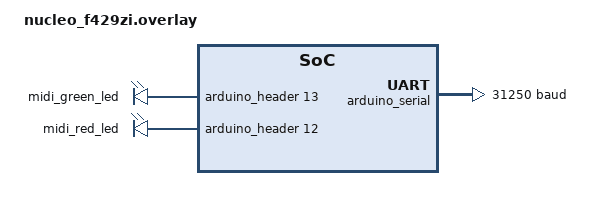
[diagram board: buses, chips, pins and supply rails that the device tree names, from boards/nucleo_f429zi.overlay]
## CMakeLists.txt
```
# Copyright (c) 2025 Titouan Christophe
# SPDX-License-Identifier: Apache-2.0

cmake_minimum_required(VERSION 3.20.0)

find_package(Zephyr REQUIRED HINTS $ENV{ZEPHYR_BASE})
project(netmidi2)

target_sources(app PRIVATE src/main.c)

include(${ZEPHYR_BASE}/samples/net/common/common.cmake)
```

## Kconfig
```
# Copyright (c) 2025 Titouan Christophe
# SPDX-License-Identifier: Apache-2.0

menu "Networking MIDI2 sample application"

config NET_SAMPLE_MIDI2_ACTIVITY_LED
	bool "Light up an LED while sending on the serial MIDI1 port"
	depends on $(dt_nodelabel_enabled,midi_green_led)
	select GPIO
	default y

config NET_SAMPLE_MIDI_HOST_PORT
	int "Host MIDI2 endpoint on this port"
	default 45486

choice NET_SAMPLE_MIDI2_AUTH_TYPE
	prompt "UMP Endpoint authentication method"
	default NET_SAMPLE_MIDI2_AUTH_NONE

config NET_SAMPLE_MIDI2_AUTH_NONE
	bool "No authentication"

config NET_SAMPLE_MIDI2_AUTH_SHARED_SECRET
	bool "Authentication with shared secret"
	select NETMIDI2_HOST_AUTH

config NET_SAMPLE_MIDI2_AUTH_USER_PASSWORD
	bool "Authentication with username+password"
	select NETMIDI2_HOST_AUTH

endchoice

config NET_SAMPLE_MIDI2_SHARED_SECRET
	string "Shared secret"
	depends on NET_SAMPLE_MIDI2_AUTH_SHARED_SECRET

config NET_SAMPLE_MIDI2_USERNAME
	string "Username"
	depends on NET_SAMPLE_MIDI2_AUTH_USER_PASSWORD

config NET_SAMPLE_MIDI2_PASSWORD
	string "Password"
	depends on NET_SAMPLE_MIDI2_AUTH_USER_PASSWORD

endmenu

source "Kconfig.zephyr"
```

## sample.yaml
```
common:
  harness: net
  tags:
    - net
sample:
  description: Test UDP transport for Universal MIDI Packets
  name: Network MIDI2
```

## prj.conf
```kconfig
CONFIG_LOG=y
CONFIG_LOG_MODE_IMMEDIATE=y
CONFIG_SYSTEM_WORKQUEUE_STACK_SIZE=8192

CONFIG_ZVFS_POLL_MAX=4

CONFIG_NETWORKING=y
CONFIG_NET_LOG=y
CONFIG_NET_IPV4=y
CONFIG_NET_UDP=y
CONFIG_NET_SOCKETS=y
CONFIG_NET_STATISTICS=y
CONFIG_NET_SOCKETS_SERVICE_STACK_SIZE=2048

CONFIG_NET_CONFIG_MY_IPV4_ADDR="192.0.2.1"
CONFIG_NET_CONFIG_NEED_IPV4=y
CONFIG_NET_CONFIG_SETTINGS=y

CONFIG_NET_HOSTNAME_ENABLE=y
CONFIG_MDNS_RESPONDER=y
CONFIG_DNS_SD=y

CONFIG_MBEDTLS=y
CONFIG_MBEDTLS_CIPHER_CCM_ENABLED=y

CONFIG_CRYPTO=y
CONFIG_CRYPTO_MBEDTLS_SHIM=y
```

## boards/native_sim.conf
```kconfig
CONFIG_NET_CONFIG_MY_IPV4_ADDR="192.0.2.1"
```

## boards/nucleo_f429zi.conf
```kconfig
CONFIG_NET_CONFIG_MY_IPV4_ADDR=""
CONFIG_NET_DHCPV4=y
```

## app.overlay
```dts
/*
 * Copyright (c) 2025 Titouan Christophe
 *
 * SPDX-License-Identifier: Apache-2.0
 */

/ {
	midi2: zephyr-midi2 {
		compatible = "zephyr,midi2-device";
		status = "okay";
		#address-cells = <1>;
		#size-cells = <1>;
		label = "Zephyr-UDP-MIDI2";

		midi2@0 {
			reg = <0 4>;
			label = "Synthesizer";
			protocol = "midi2";
		};

		midi1@8 {
			reg = <8 1>;
			protocol = "midi1-up-to-64b";
			terminal-type = "input-only";
			label = "Keyboard";
		};

		ext_midi_out: midi1@9 {
			reg = <9 1>;
			protocol = "midi1-up-to-64b";
			terminal-type = "output-only";
			label = "External output (MIDI DIN-5)";
			serial-31250bps;
		};
	};
};
```

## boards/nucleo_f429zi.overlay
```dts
#include "../app.overlay"

/ {
	aliases {
		midi-tx-uart = &arduino_serial;
		midi-tx-led = &midi_green_led;
	};

	leds {
		midi_green_led: midi-green-led {
			gpios = <&arduino_header 13 GPIO_ACTIVE_HIGH>;
		};

		midi_red_led: midi-red-led {
			gpios = <&arduino_header 12 GPIO_ACTIVE_HIGH>;
		};
	};
};

&arduino_serial {
	current-speed = <31250>;
};
```

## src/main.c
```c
/*
 * Copyright (c) 2025 Titouan Christophe
 * SPDX-License-Identifier: Apache-2.0
 */

#include <zephyr/kernel.h>
#include <errno.h>
#include <stdio.h>

#include <zephyr/audio/midi.h>
#include <zephyr/net/dns_sd.h>
#include <zephyr/net/midi2.h>

#include <ump_stream_responder.h>

#include <zephyr/logging/log.h>
LOG_MODULE_REGISTER(net_midi2_sample, LOG_LEVEL_DBG);

#define ACT_LED_NODE DT_NODELABEL(midi_green_led)
#define SERIAL_NODE  DT_NODELABEL(midi_serial)

#if !defined(CONFIG_NET_SAMPLE_MIDI2_ACTIVITY_LED)
#define CONFIGURE_LED()
#define SET_LED(_state)
#else /* CONFIG_NET_SAMPLE_MIDI2_ACTIVITY_LED */
#include <zephyr/drivers/gpio.h>

static const struct gpio_dt_spec act_led = GPIO_DT_SPEC_GET(ACT_LED_NODE, gpios);

#define CONFIGURE_LED() gpio_pin_configure_dt(&act_led, GPIO_OUTPUT_INACTIVE)
#define SET_LED(_state) gpio_pin_set_dt(&act_led, (_state))
#endif  /* CONFIG_NET_SAMPLE_MIDI2_ACTIVITY_LED */


#if !DT_NODE_EXISTS(SERIAL_NODE)
#define send_external_midi1(...)
#else /* DT_NODE_EXISTS(SERIAL_NODE) */
#include <zephyr/drivers/uart.h>

static const struct device *const uart_dev = DEVICE_DT_GET(SERIAL_NODE);

static inline void send_external_midi1(const struct midi_ump ump)
{
	/* Only send MIDI events aimed at the external output */
	if (UMP_GROUP(ump) != DT_REG_ADDR(DT_NODELABEL(ext_midi_out))) {
		return;
	}

	switch (UMP_MIDI_COMMAND(ump)) {
	case UMP_MIDI_PROGRAM_CHANGE:
		SET_LED(1);
		uart_poll_out(uart_dev, UMP_MIDI_STATUS(ump));
		uart_poll_out(uart_dev, UMP_MIDI1_P1(ump));
		SET_LED(0);
		break;

	case UMP_MIDI_NOTE_OFF:
	case UMP_MIDI_NOTE_ON:
	case UMP_MIDI_AFTERTOUCH:
	case UMP_MIDI_CONTROL_CHANGE:
	case UMP_MIDI_PITCH_BEND:
		SET_LED(1);
		uart_poll_out(uart_dev, UMP_MIDI_STATUS(ump));
		uart_poll_out(uart_dev, UMP_MIDI1_P1(ump));
		uart_poll_out(uart_dev, UMP_MIDI1_P2(ump));
		SET_LED(0);
		break;
	}
}
#endif /* DT_NODE_EXISTS(SERIAL_NODE) */

#define MIDI2_NODE DT_NODELABEL(midi2)

static const struct ump_endpoint_dt_spec ump_ep_dt =
	UMP_ENDPOINT_DT_SPEC_GET(MIDI2_NODE);

static inline void handle_ump_stream(struct netmidi2_session *session,
				     const struct midi_ump ump)
{
	const struct ump_stream_responder_cfg responder_cfg =
		UMP_STREAM_RESPONDER(session, netmidi2_send, &ump_ep_dt);
	ump_stream_respond(&responder_cfg, ump);
}

#if defined(CONFIG_NET_SAMPLE_MIDI2_AUTH_NONE)
/* Simple Network MIDI 2.0 endpoint without authentication */
NETMIDI2_EP_DEFINE(midi_server, DT_PROP_OR(MIDI2_NODE, label, NULL), NULL, htons(CONFIG_NET_SAMPLE_MIDI_HOST_PORT));

#elif defined(CONFIG_NET_SAMPLE_MIDI2_AUTH_SHARED_SECRET)
/* Network MIDI 2.0 endpoint with shared secret authentication */
BUILD_ASSERT(
	sizeof(CONFIG_NET_SAMPLE_MIDI2_SHARED_SECRET) > 1,
	"CONFIG_NET_SAMPLE_MIDI2_SHARED_SECRET must be not empty"
);


NETMIDI2_EP_DEFINE_WITH_AUTH(midi_server, DT_PROP_OR(MIDI2_NODE, label, NULL), NULL, htons(CONFIG_NET_SAMPLE_MIDI_HOST_PORT),
	CONFIG_NET_SAMPLE_MIDI2_SHARED_SECRET);

#elif defined(CONFIG_NET_SAMPLE_MIDI2_AUTH_USER_PASSWORD)
/* Network MIDI 2.0 endpoint with a single user/password*/
BUILD_ASSERT(
	sizeof(CONFIG_NET_SAMPLE_MIDI2_USERNAME) > 1,
	"CONFIG_NET_SAMPLE_MIDI2_USERNAME must be not empty"
);
BUILD_ASSERT(
	sizeof(CONFIG_NET_SAMPLE_MIDI2_PASSWORD) > 1,
	"CONFIG_NET_SAMPLE_MIDI2_PASSWORD must be not empty"
);


NETMIDI2_EP_DEFINE_WITH_USERS(midi_server, DT_PROP_OR(MIDI2_NODE, label, NULL), NULL, htons(CONFIG_NET_SAMPLE_MIDI_HOST_PORT),
	{.name = CONFIG_NET_SAMPLE_MIDI2_USERNAME,
	 .password = CONFIG_NET_SAMPLE_MIDI2_PASSWORD});

#endif

DNS_SD_REGISTER_SERVICE(midi_dns, CONFIG_NET_HOSTNAME "-" CONFIG_BOARD,
			"_midi2", "_udp", "local", DNS_SD_EMPTY_TXT,
			&midi_server.addr4.sin_port);

static void rx_ump(struct netmidi2_session *session, const struct midi_ump ump)
{
	switch (UMP_MT(ump)) {
	case UMP_MT_MIDI1_CHANNEL_VOICE:
		send_external_midi1(ump);
	case UMP_MT_UMP_STREAM:
		handle_ump_stream(session, ump);
		break;
	}
}

static void session_established(struct netmidi2_session *session)
{
	LOG_INF("New client session established %p", session);
}

static void session_closed(struct netmidi2_session *session)
{
	LOG_INF("Client session closing %p", session);
}

int main(void)
{
	CONFIGURE_LED();

	netmidi2_set_ops(&midi_server, &((const struct netmidi2_ops) {
		.rx_packet_cb = rx_ump,
		.session_established_cb = session_established,
		.session_closed_cb = session_closed,
	}));
	netmidi2_host_ep_start(&midi_server);

	return 0;
}
```

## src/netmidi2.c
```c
#include "netmidi2.h"

#include <stdio.h>
#include <zephyr/crypto/crypto.h>

#include <zephyr/logging/log.h>
LOG_MODULE_REGISTER(udp_midi, LOG_LEVEL_INF);

#define BUFSIZE 256

NET_BUF_POOL_DEFINE(udp_midi_pool, 10, BUFSIZE, 0, NULL);

#define SESS_LOG_DBG(_s, _fmt, ...) SESS_LOG(DBG, _s, _fmt, ##__VA_ARGS__)
#define SESS_LOG_INF(_s, _fmt, ...) SESS_LOG(INF, _s, _fmt, ##__VA_ARGS__)
#define SESS_LOG_WRN(_s, _fmt, ...) SESS_LOG(WRN, _s, _fmt, ##__VA_ARGS__)
#define SESS_LOG_ERR(_s, _fmt, ...) SESS_LOG(ERR, _s, _fmt, ##__VA_ARGS__)

#define SESS_LOG(_lvl, _s, _fmt, ...) \
	{ \
		const struct sockaddr_in *__pa = (const struct sockaddr_in *) &(_s)->addr; \
		char __pn[INET_ADDRSTRLEN]; \
		net_addr_ntop(AF_INET, &__pa->sin_addr, __pn, INET_ADDRSTRLEN); \
		LOG_##_lvl("%s:%d " _fmt, __pn, __pa->sin_port, ##__VA_ARGS__); \
	}

static inline bool udp_midi_session_has_state(struct udp_midi_session *session,
					      enum udp_midi_session_state state)
{
	if (! session) {
		return false;
	}
	return session->state == state;
}

static inline void udp_midi_free_session(struct udp_midi_session *session)
{
	SESS_LOG_INF(session, "Free client session");

	k_work_cancel(&session->tx_work);
	if (session->tx_buf) {
		net_buf_unref(session->tx_buf);
	}
	memset(session, 0, sizeof(*session) - sizeof(struct k_work));
}

static inline struct udp_midi_session *udp_midi_match_session(
	struct udp_midi_ep *ep,
	struct sockaddr *peer_addr,
	socklen_t peer_addr_len
)
{
	for (size_t i=0; i<ep->n_peers; i++) {
		if (
			ep->peers[i].addr_len == peer_addr_len &&
			memcmp(&ep->peers[i].addr, peer_addr, peer_addr_len) == 0
		) {
			LOG_DBG("Found matching client session %d", i);
			return &ep->peers[i];
		}
	}

	return NULL;
}

static inline void udp_midi_free_inactive_sessions(struct udp_midi_ep *ep)
{
	struct udp_midi_session *sess;
	const uint8_t bye_timeout[] = {COMMAND_BYE, 0, 0x04, 0};

	for (size_t i=0; i<ep->n_peers; i++) {
		sess = &ep->peers[i];
		switch (sess->state) {
		case IDLE:
		case PENDING_INVITATION:
		case AUTHENTICATION_REQUIRED:
		case PENDING_BYE:
			SESS_LOG_WRN(sess, "Cleanup inactive session");
			zsock_sendto(ep->sock, bye_timeout, sizeof(bye_timeout),
				     0, &sess->addr, sess->addr_len);
			udp_midi_free_session(sess);
		default:
			continue;
		}
	}
}

static inline struct udp_midi_session *udp_midi_try_alloc_session(
	struct udp_midi_ep *ep,
	struct sockaddr *peer_addr,
	socklen_t peer_addr_len
)
{
	struct udp_midi_session *sess;

	for (size_t i=0; i<ep->n_peers; i++) {
		sess = &ep->peers[i];
		if (sess->state == NOT_INITIALIZED) {
			sess->state = IDLE;
			sess->addr_len = peer_addr_len;
			sess->ep = ep;
			memcpy(&sess->addr, peer_addr, peer_addr_len);
			SESS_LOG_INF(sess, "new client session (%d)", i);
			return sess;
		}
	}

	return NULL;
}

static inline struct udp_midi_session *udp_midi_alloc_session(
	struct udp_midi_ep *ep,
	struct sockaddr *peer_addr,
	socklen_t peer_addr_len
)
{
	struct udp_midi_session *res = udp_midi_try_alloc_session(ep, peer_addr, peer_addr_len);
	if (! res) {
		udp_midi_free_inactive_sessions(ep);
		res = udp_midi_try_alloc_session(ep, peer_addr, peer_addr_len);
	}

	if (! res) {
		LOG_ERR("No available client session");
	}

	return res;
}

static inline const struct udp_midi_user *udp_midi_find_user(
	const struct udp_midi_ep *ep, const char *name, size_t namelen
)
{
	if (ep->auth_type != UDP_MIDI_USER_PASSWORD) {
		return NULL;
	}

	for (size_t i=0; i<ep->userlist->n_users; i++) {
		if (strncmp(ep->userlist->users[i].name, name, namelen) == 0) {
			return &ep->userlist->users[i];
		}
	}

	return NULL;
}

static inline bool udp_midi_auth_session(const struct udp_midi_session *sess,
					 struct net_buf_simple *buf)
{
	const struct device *hasher = device_get_binding(CONFIG_CRYPTO_MBEDTLS_SHIM_DRV_NAME);
	struct hash_ctx ctx = {.flags = crypto_query_hwcaps(hasher)};
	const uint8_t *auth_digest = buf->data;
	const struct udp_midi_user *user;
	uint8_t input[64];
	uint8_t output[32];
	size_t secret_len = strlen(sess->ep->shared_auth_secret);
	struct hash_pkt hash = {
		.in_buf = input,
		.in_len = UDP_MIDI_NONCE_SIZE,
		.out_buf = output,
	};

	/* Remove digest from buffer */
	net_buf_simple_pull(buf, 32);

	if (! hasher) {
		LOG_ERR("mbedtls crypto pseudo-device unavailable");
		return false;
	}

	memcpy(input, sess->nonce, UDP_MIDI_NONCE_SIZE);

	if (sess->ep->auth_type == UDP_MIDI_SHARED_SECRET) {
		memcpy(&input[UDP_MIDI_NONCE_SIZE], sess->ep->shared_auth_secret, secret_len);
		hash.in_len += secret_len;
	} else if (sess->ep->auth_type == UDP_MIDI_USER_PASSWORD) {
		user = udp_midi_find_user(sess->ep, buf->data, buf->len);
		if (! user) {
			LOG_ERR("No matching user found");
			return false;
		}
		hash.in_len += snprintf(&input[UDP_MIDI_NONCE_SIZE],
					sizeof(input) - UDP_MIDI_NONCE_SIZE,
					"%s%s", user->name, user->password);
		/* Remove username from buffer */
		net_buf_simple_pull(buf, ROUND_UP(strlen(user->name), 4));
	}

	hash_begin_session(hasher, &ctx, CRYPTO_HASH_ALGO_SHA256);

	if (hash_compute(&ctx, &hash)) {
		SESS_LOG_ERR(sess, "Hashing error");
		return false;
	}

	hash_free_session(hasher, &ctx);

	return memcmp(hash.out_buf, auth_digest, 32) == 0;
}

static int udp_midi_dispatch_command_packet(struct udp_midi_ep *ep,
					    struct sockaddr *peer_addr,
					    socklen_t peer_addr_len,
					    struct net_buf_simple *rx,
					    struct net_buf_simple *tx)
{
	struct midi_ump ump;
	size_t payload_len;
	uint8_t cmd_code, payload_len_words;
	uint16_t cmd_data;
	struct udp_midi_session *session;

	if (rx->len < 4) {
		LOG_ERR("Incomplete UDP MIDI command packet header");
		return -1;
	}

	cmd_code = net_buf_simple_pull_u8(rx);
	payload_len_words = net_buf_simple_pull_u8(rx);
	payload_len = 4 * payload_len_words;
	cmd_data = net_buf_simple_pull_be16(rx);

	if (payload_len > rx->len) {
		LOG_ERR("Incomplete UDP MIDI command packet payload");
		return -1;
	}

	switch (cmd_code) {
	case COMMAND_PING:
		if (payload_len_words != 1) {
			LOG_ERR("Invalid payload length for PING packet");
			return -1;
		}
		net_buf_simple_add_u8(tx, COMMAND_PING_REPLY);
		net_buf_simple_add_u8(tx, 1);
		net_buf_simple_add_be16(tx, 0);
		/* PING id */
		net_buf_simple_add_be32(tx, net_buf_simple_pull_be32(rx));
		return 0;

	case COMMAND_INVITATION:
		net_buf_simple_pull(rx, payload_len);

		session = udp_midi_alloc_session(ep, peer_addr, peer_addr_len);
		if (! session) {
			return -1;
		}

		if (ep->auth_type == UDP_MIDI_NO_AUTH) {
			net_buf_simple_add_u8(tx, COMMAND_INVITATION_REPLY_ACCEPTED);
			net_buf_simple_add_be24(tx, 0);
			session->state = ESTABLISHED_SESSION;
		} else {
			net_buf_simple_add_u8(tx, ep->auth_type == UDP_MIDI_SHARED_SECRET
						  ? COMMAND_INVITATION_REPLY_AUTH_REQUIRED
						  : COMMAND_INVITATION_REPLY_USER_AUTH_REQUIRED);
			net_buf_simple_add_u8(tx, 4);
			net_buf_simple_add_be16(tx, 0);
			memcpy(session->nonce, "nUWrn*@#$hjfwnkL", UDP_MIDI_NONCE_SIZE);
			net_buf_simple_add_mem(tx, session->nonce, UDP_MIDI_NONCE_SIZE);
			session->state = AUTHENTICATION_REQUIRED;
		}

		return 0;

	case COMMAND_INVITATION_WITH_AUTH:
	case COMMAND_INVITATION_WITH_USER_AUTH:
		session = udp_midi_match_session(ep, peer_addr, peer_addr_len);
		if (! udp_midi_session_has_state(session, AUTHENTICATION_REQUIRED)) {
			LOG_WRN("No session to authenticate found");
			return -1;
		}

		if (payload_len_words < 8) {
			SESS_LOG_WRN(session, "Invalid auth digest length");
			return -1;
		}

		if (! udp_midi_auth_session(session, rx)) {
			SESS_LOG_WRN(session, "Invalid auth digest");
			return -1;
		}

		net_buf_simple_add_u8(tx, COMMAND_INVITATION_REPLY_ACCEPTED);
		net_buf_simple_add_be24(tx, 0);
		session->state = ESTABLISHED_SESSION;
		return 0;

	case COMMAND_BYE:
		session = udp_midi_match_session(ep, peer_addr, peer_addr_len);
		if (! session) {
			LOG_WRN("Receiving BYE without session");
			return -1;
		}
		net_buf_simple_pull(rx, payload_len);
		net_buf_simple_add_u8(tx, COMMAND_BYE_REPLY);
		net_buf_simple_add_be24(tx, 0);
		udp_midi_free_session(session);
		return 0;

	case COMMAND_UMP_DATA:
		session = udp_midi_match_session(ep, peer_addr, peer_addr_len);
		if (! udp_midi_session_has_state(session, ESTABLISHED_SESSION)) {
			LOG_WRN("Receiving UMP data without established session");
			return -1;
		}

		if (session->rx_ump_seq == cmd_data) {
			session->rx_ump_seq++;
		} else {
			SESS_LOG_WRN(session, "UMP Rx sequence mismatch (got %d, expected %d)",
				     cmd_data, session->rx_ump_seq);
			session->rx_ump_seq = 1 + cmd_data;
		}

		if (payload_len_words < 1 || payload_len_words > 4) {
			SESS_LOG_ERR(session, "Invalid UMP length");
			return -1;
		}

		for (size_t i=0; i<payload_len_words; i++) {
			ump.data[i] = net_buf_simple_pull_be32(rx);
		}

		if (UMP_NUM_WORDS(ump) != payload_len_words) {
			SESS_LOG_ERR(session, "Invalid UMP payload size for its message type");
			return -1;
		}

		if (ep->rx_packet_cb){
			ep->rx_packet_cb(session, ump);
		}
		return 0;

	case COMMAND_SESSION_RESET:
		session = udp_midi_match_session(ep, peer_addr, peer_addr_len);
		if (! udp_midi_session_has_state(session, ESTABLISHED_SESSION)) {
			LOG_WRN("Receiving session reset without established session");
			return -1;
		}

		session->tx_ump_seq = 0;
		session->rx_ump_seq = 0;
		SESS_LOG_INF(session, "Reset session");
		net_buf_simple_add_u8(tx, COMMAND_SESSION_RESET_REPLY);
		net_buf_simple_add_be24(tx, 0);
		return 0;

	default:
		LOG_WRN("Unknown command code %02X", cmd_code);
		net_buf_simple_pull(rx, payload_len);
		// TODO: send NAK "Command not supported"
		return 0;
	}
	return 0;
}

static void udp_midi_rx_work(struct k_work *work)
{
	int ret;
	struct sockaddr peer_addr;
	socklen_t peer_addr_len = sizeof(peer_addr);
	struct udp_midi_ep *ep = CONTAINER_OF(work, struct udp_midi_ep, rx_work);
	struct net_buf_simple *rxbuf = NET_BUF_SIMPLE(BUFSIZE);
	struct net_buf_simple *txbuf = NET_BUF_SIMPLE(BUFSIZE);

	net_buf_simple_init(rxbuf, 0);
	net_buf_simple_init(txbuf, 0);

	/* Receive packet */
	LOG_DBG("Waiting for new UDP packet...");

	ret = zsock_recvfrom(ep->sock, rxbuf->data, rxbuf->size, 0, &peer_addr, &peer_addr_len);
	if (ret < 0) {
		LOG_ERR("Rx error: %d (%d)", ret, errno);
		goto end;
	}
	rxbuf->len = ret;

	LOG_HEXDUMP_DBG(rxbuf->data, rxbuf->len, "Received UDP packet");

	/* Check for magic header */
	if (rxbuf->len < 4 || memcmp(rxbuf->data, "MIDI", 4) != 0) {
		LOG_WRN("Not a MIDI packet");
		goto end;
	}

	net_buf_simple_pull(rxbuf, 4);
	net_buf_simple_add_mem(txbuf, "MIDI", 4);

	/* Parse contained command packets */
	while (
		rxbuf->len >= 4 &&
		udp_midi_dispatch_command_packet(ep, &peer_addr, peer_addr_len, rxbuf, txbuf) == 0
	);

	/* Send reply if non empty */
	if (txbuf->len > 4) {
		LOG_HEXDUMP_DBG(txbuf->data, txbuf->len, "Sending UDP packet...");
		ret = zsock_sendto(ep->sock, txbuf->data, txbuf->len, 0, &peer_addr, peer_addr_len);
		if (ret < 0) {
			LOG_ERR("Unable to send reply: %d", errno);
		}
	}

	end:
		k_work_submit(&ep->rx_work);
}

static void udp_midi_session_tx_work(struct k_work *work)
{
	struct udp_midi_session *session = CONTAINER_OF(work, struct udp_midi_session, tx_work);
	struct net_buf *buf = session->tx_buf;
	session->tx_buf = NULL;

	zsock_sendto(session->ep->sock, buf->data, buf->len, 0,
		     &session->addr, session->addr_len);
	net_buf_unref(buf);
}

int udp_midi_ep_start(struct udp_midi_ep *ep,
		      const struct sockaddr *addr, socklen_t addr_len)
{
	int ret;
	memset(ep->peers, 0, ep->n_peers * sizeof(ep->peers[0]));

	ep->sock = zsock_socket(AF_INET, SOCK_DGRAM, IPPROTO_UDP);
	if (ep->sock < 0) {
		LOG_ERR("Unable to create socket: %d", errno);
		return -1;
	}

	ret = zsock_bind(ep->sock, addr, addr_len);
	if (ret < 0) {
		LOG_ERR("Failed to bind UDP socket: %d", errno);
		ret = -errno;
	}

	k_work_init(&ep->rx_work, udp_midi_rx_work);
	k_work_submit(&ep->rx_work);

	for (size_t i=0; i<ep->n_peers; i++) {
		k_work_init(&ep->peers[i].tx_work, udp_midi_session_tx_work);
	}

	return ret;
}

void udp_midi_broadcast(struct udp_midi_ep *ep, const struct midi_ump ump)
{
	for (size_t i=0; i<ep->n_peers; i++) {
		if (ep->peers[i].state == ESTABLISHED_SESSION){
			udp_midi_send(&ep->peers[i], ump);
		}
	}
}

void udp_midi_send(struct udp_midi_session *sess, const struct midi_ump ump)
{
	if (! sess->tx_buf){
		sess->tx_buf = net_buf_alloc(&udp_midi_pool, K_FOREVER);
		net_buf_add_be32(sess->tx_buf, 0x4d494449);
	}

	if (net_buf_tailroom(sess->tx_buf) < 4*(1 + UMP_NUM_WORDS(ump))) {
		LOG_WRN("Not enough room in Tx buffer");
		return;
	}

	net_buf_add_u8(sess->tx_buf, COMMAND_UMP_DATA);
	net_buf_add_u8(sess->tx_buf, UMP_NUM_WORDS(ump));
	net_buf_add_be16(sess->tx_buf, sess->tx_ump_seq++);

	for (size_t i=0; i<UMP_NUM_WORDS(ump); i++){
		net_buf_add_be32(sess->tx_buf, ump.data[i]);
	}
	k_work_submit(&sess->tx_work);
}
```

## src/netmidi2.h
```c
/*
 * Copyright (c) 2025 Titouan Christophe
 *
 * SPDX-License-Identifier: Apache-2.0
 */

#ifndef NETMIDI2_H_
#define NETMIDI2_H_

#include <stdint.h>
#include <zephyr/net/socket.h>
#include <zephyr/audio/midi.h>

#define CLIENT_CAP_INV_WITH_AUTH	BIT(0)
#define CLIENT_CAP_INV_WITH_USER_AUTH	BIT(1)

#define COMMAND_INVITATION 0x01
#define COMMAND_INVITATION_WITH_AUTH 0x02
#define COMMAND_INVITATION_WITH_USER_AUTH 0x03
#define COMMAND_INVITATION_REPLY_ACCEPTED 0x10
#define COMMAND_INVITATION_REPLY_PENDING 0x11
#define COMMAND_INVITATION_REPLY_AUTH_REQUIRED 0x12
#define COMMAND_INVITATION_REPLY_USER_AUTH_REQUIRED 0x13
#define COMMAND_PING 0x20
#define COMMAND_PING_REPLY 0x21
#define COMMAND_RETRANSMIT_REQUEST 0x80
#define COMMAND_RETRANSMIT_ERROR 0x81
#define COMMAND_SESSION_RESET 0x82
#define COMMAND_SESSION_RESET_REPLY 0x83
#define COMMAND_NAK 0x8F
#define COMMAND_BYE 0xF0
#define COMMAND_BYE_REPLY 0xF1
#define COMMAND_UMP_DATA 0xFF

#define UDP_MIDI_EP_DECLARE(_name, _n_peers) \
	static struct udp_midi_session peers_of_##_name[_n_peers]; \
	static struct udp_midi_ep _name = {.n_peers = _n_peers, .peers = peers_of_##_name}

enum udp_midi_session_state {
	NOT_INITIALIZED = 0,
	IDLE,
	PENDING_INVITATION,
	AUTHENTICATION_REQUIRED,
	ESTABLISHED_SESSION,
	PENDING_SESSION_RESET,
	PENDING_BYTE,
};

struct udp_midi_ep;

#define UDP_MIDI_NONCE_SIZE 16

struct udp_midi_user {
	const char *name;
	const char *password;
};

struct udp_midi_userlist {
	size_t n_users;
	const struct udp_midi_user users[];
};

struct udp_midi_session {
	enum udp_midi_session_state state;
	uint16_t tx_ump_seq;
	uint16_t rx_ump_seq;
	struct sockaddr addr;
	socklen_t addr_len;
	const struct udp_midi_ep *ep;
	const struct udp_midi_user *user;
	char nonce[UDP_MIDI_NONCE_SIZE];
	struct net_buf *tx_buf;
	struct k_work tx_work;
};

enum udp_midi_auth_type {
	UDP_MIDI_NO_AUTH,
	UDP_MIDI_SHARED_SECRET,
	UDP_MIDI_USER_PASSWORD,
};

struct udp_midi_ep {
	int sock;
	struct k_work rx_work;
	void (*rx_packet_cb)(struct udp_midi_session *session,
			     const struct midi_ump ump);
	size_t n_peers;
	struct udp_midi_session *peers;
	enum udp_midi_auth_type auth_type;
	union {
		const char *shared_auth_secret;
		const struct udp_midi_userlist *userlist;
	};
};

int udp_midi_ep_start(struct udp_midi_ep *ep,
		      const struct sockaddr *addr, socklen_t addr_len);

/**
 * @brief      Send a Universal MIDI Packet to all clients connected to the endpoint
 * @param      ep    The endpoint
 * @param[in]  ump   The packet to send
 */
void udp_midi_broadcast(struct udp_midi_ep *ep, const struct midi_ump ump);

/**
 * @brief      Send a Universal MIDI Packet to a single client
 * @param      sess  The session identifying the single client
 * @param[in]  ump   The packet to send
 */
void udp_midi_send(struct udp_midi_session *sess, const struct midi_ump ump);

#endif
```

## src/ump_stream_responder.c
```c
#include "ump_stream_responder.h"

#include <string.h>
#include <zephyr/devicetree.h>
#include <zephyr/sys/byteorder.h>

#include <zephyr/logging/log.h>
LOG_MODULE_REGISTER(ump_stream_responder);

#define BIT_IF(cond, n) ((cond) ? BIT(n) : 0)

/**
 * @brief      Build an Endpoint Info Notification Universal MIDI Packet
 * @see        ump112: 7.1.2 Endpoint Info Notification Message
 */
static inline struct midi_ump make_endpoint_info(const struct ump_endpoint_dt_spec *ep)
{
	bool has_midi1 = false;
	bool has_midi2 = false;
	struct midi_ump res;

	for (size_t i=0; i<ep->n_blocks; i++) {
		if (ep->blocks[i].is_midi1) {
			has_midi1 = true;
		} else {
			has_midi2 = true;
		}
	}

	res.data[0] = (UMP_MT_UMP_STREAM << 28)
                    | (UMP_STREAM_STATUS_EP_INFO << 16)
                    | ((1) << 8) | (1); /* UMP version 1.1 */

        res.data[1] = (1 << 31) /* Static function blocks */
                    | ((ep->n_blocks) << 24)
                    | BIT_IF(has_midi2, 9)
                    | BIT_IF(has_midi1, 8);

	return res;
}

/**
 * @brief      Build a Function Block Info Notification Universal MIDI Packet
 * @see        ump112: 7.1.8 Function Block Info Notification
 */
static inline struct midi_ump make_function_block_info(const struct ump_endpoint_dt_spec *ep, size_t block_num)
{
	const struct ump_block_dt_spec *block = &ep->blocks[block_num];
	struct midi_ump res;
	uint8_t midi1_mode = block->is_31250bps ? 2 : block->is_midi1 ? 1 : 0;

	res.data[0] = (UMP_MT_UMP_STREAM << 28)
		    | (UMP_STREAM_STATUS_FB_INFO << 16)
		    | (1 << 15)  /* Block is active */
		    | (block_num << 8)
		    | BIT_IF(block->is_output, 5) /* UI hint Sender */
		    | BIT_IF(block->is_input, 4)  /* UI hint Receiver */
		    | (midi1_mode << 2)
		    | BIT_IF(block->is_output, 1) /* Function block is output */
		    | BIT_IF(block->is_input, 0); /* Function block is input */

	res.data[1] = (block->first_group << 24)
		    | (block->groups_spanned << 16)
		    | (0x01 << 8)  /* MIDI-CI support for UMP spec 1.1 */
		    | 0xff;  /* At most 255 simultaneous Sysex streams */

	return res;
}

static inline size_t fill_str(struct midi_ump *ump, size_t offset,
			      const char *src, size_t len)
{
	size_t i, j;

	if (offset >= sizeof(struct midi_ump)) {
		return 0;
	}

	for (i=0; i<len && (j = i + offset) < sizeof(struct midi_ump); i++) {
		ump->data[j / 4] |= src[i] << (8 * (3 - (j % 4)));
	}

	return i;
}

/**
 * @brief      Send a string as UMP Stream, possibly splitting into multiple
 *             packets if the string length is larger
 * @param[in]  cfg     The responder configuration
 * @param[in]  string  The string to send
 * @param[in]  prefix  The fixed prefix of UMP packets to send
 * @param[in]  offset  The offset the strings starts in the packet, in bytes
 *
 * @return     The number of packets sent
 */
static inline int send_string(const struct ump_stream_responder_cfg *cfg,
			      const char *string,
			      uint32_t prefix, size_t offset)
{
	struct midi_ump reply;
	size_t stringlen = strlen(string);
	size_t strwidth = sizeof(reply) - offset;
	uint8_t format;
	size_t i = 0;
	int res = 0;

	while (i < stringlen) {
		memset(&reply, 0, sizeof(reply));
		format = (i == 0)
			? (stringlen - i <= strwidth)
				? UMP_STREAM_FORMAT_COMPLETE
				: UMP_STREAM_FORMAT_START
			: (stringlen - i > strwidth)
				? UMP_STREAM_FORMAT_CONTINUE
				: UMP_STREAM_FORMAT_END;

		reply.data[0] = (UMP_MT_UMP_STREAM << 28)
			      | (format << 26)
			      | prefix;

		i += fill_str(&reply, offset, &string[i], stringlen - i);
		cfg->send(cfg->dev, reply);
		res++;
	}

	return res;
}

static inline int ump_ep_discover(const struct ump_stream_responder_cfg *cfg,
				  const struct midi_ump pkt)
{
	int res = 0;
	uint8_t vmaj = UMP_STREAM_EP_DISCOVERY_VMAJ(pkt);
	uint8_t vmin = UMP_STREAM_EP_DISCOVERY_VMIN(pkt);
	uint8_t filter = UMP_STREAM_EP_DISCOVERY_FILTER(pkt);
	LOG_DBG("Endpoint discovery ump v%d.%d filter=%02X", vmaj, vmin, filter);

	/* Request for Endpoint Info Notification */
	if (filter & UMP_EP_DISC_FILTER_EP_INFO) {
		cfg->send(cfg->dev, make_endpoint_info(cfg->ep_spec));
		res++;
	}

	/* Request for Endpoint Name Notification */
	if (filter & UMP_EP_DISC_FILTER_EP_NAME) {
		res += send_string(cfg, cfg->ep_spec->name,
				   UMP_STREAM_STATUS_EP_NAME << 16, 2);
	}

	return res;
}

static inline int ump_fb_discover(const struct ump_stream_responder_cfg *cfg,
				  const struct midi_ump pkt)
{
	int res = 0;
	uint8_t block_num = UMP_STREAM_FB_DISCOVERY_NUM(pkt);
	uint8_t filter = UMP_STREAM_FB_DISCOVERY_FILTER(pkt);

	if (block_num >= cfg->ep_spec->n_blocks) {
		LOG_WRN("Function block discovery block=%d does not exist", block_num);
		return 0;
	}

	const struct ump_block_dt_spec *blk = &cfg->ep_spec->blocks[block_num];

	LOG_DBG("Function block discovery block=%d filter=%02X", block_num, filter);

	if (filter & UMP_FB_DISC_FILTER_INFO) {
		cfg->send(cfg->dev, make_function_block_info(cfg->ep_spec, block_num));
		res++;
	}

	if (filter & UMP_FB_DISC_FILTER_NAME) {
		res += send_string(cfg, blk->name,
				   (UMP_STREAM_STATUS_FB_NAME << 16) | (block_num << 8), 3);
	}

	return res;
}

int ump_stream_responder(const struct ump_stream_responder_cfg *cfg,
			 const struct midi_ump pkt)
{
	if (! cfg->send) {
		return -EINVAL;
	}

	if (UMP_MT(pkt) != UMP_MT_UMP_STREAM) {
		return 0;
	}

	switch (UMP_STREAM_STATUS(pkt)) {
	case UMP_STREAM_STATUS_EP_DISCOVERY:
		return ump_ep_discover(cfg, pkt);
	case UMP_STREAM_STATUS_FB_DISCOVERY:
		return ump_fb_discover(cfg, pkt);
	}

	return 0;
}
```

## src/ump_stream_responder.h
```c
#ifndef ZYNTH_UMP_DSICOVERY_H_
#define ZYNTH_UMP_DSICOVERY_H_

#include <zephyr/audio/midi.h>
#include <openamp/rpmsg.h>

struct ump_block_dt_spec {
    const char *name;
    uint8_t first_group;
    uint8_t groups_spanned;
    bool is_input;
    bool is_output;
    bool is_midi1;
};

struct ump_endpoint_dt_spec {
    const char *name;
    size_t n_blocks;
    struct ump_block_dt_spec blocks[];
};

struct ump_stream_responder_cfg {
	void *dev;
	void(*send)(void *dev, const struct midi_ump ump);
	const struct ump_endpoint_dt_spec *ep_spec;
};

#define UMP_BLOCK_DT_SPEC_GET(_node)                                   \
{                                                                      \
    .name = DT_NODE_FULL_NAME(_node),                                  \
    .first_group = DT_REG_ADDR(_node),                                 \
    .groups_spanned = DT_REG_SIZE(_node),                              \
    .is_input = !DT_ENUM_HAS_VALUE(_node, terminal_type, output_only), \
    .is_output = !DT_ENUM_HAS_VALUE(_node, terminal_type, input_only), \
    .is_midi1 = !DT_ENUM_HAS_VALUE(_node, protocol, midi2),            \
}

#define UMP_BLOCK_SEP_IF_OKAY(_node) \
    COND_CODE_1(DT_NODE_HAS_STATUS_OKAY(_node), (UMP_BLOCK_DT_SPEC_GET(_node),), ())

#define UMP_ENDPOINT_DT_SPEC_GET(_node) \
{ \
    .name = DT_NODE_FULL_NAME(_node), \
    .n_blocks = DT_FOREACH_CHILD_SEP(_node, DT_NODE_HAS_STATUS_OKAY, (+)), \
    .blocks = {DT_FOREACH_CHILD(DT_CHOSEN(zephyr_midi), UMP_BLOCK_SEP_IF_OKAY)}, \
}

int ump_stream_responder(const struct ump_stream_responder_cfg *cfg,
			 const struct midi_ump pkt);

#endif
```
